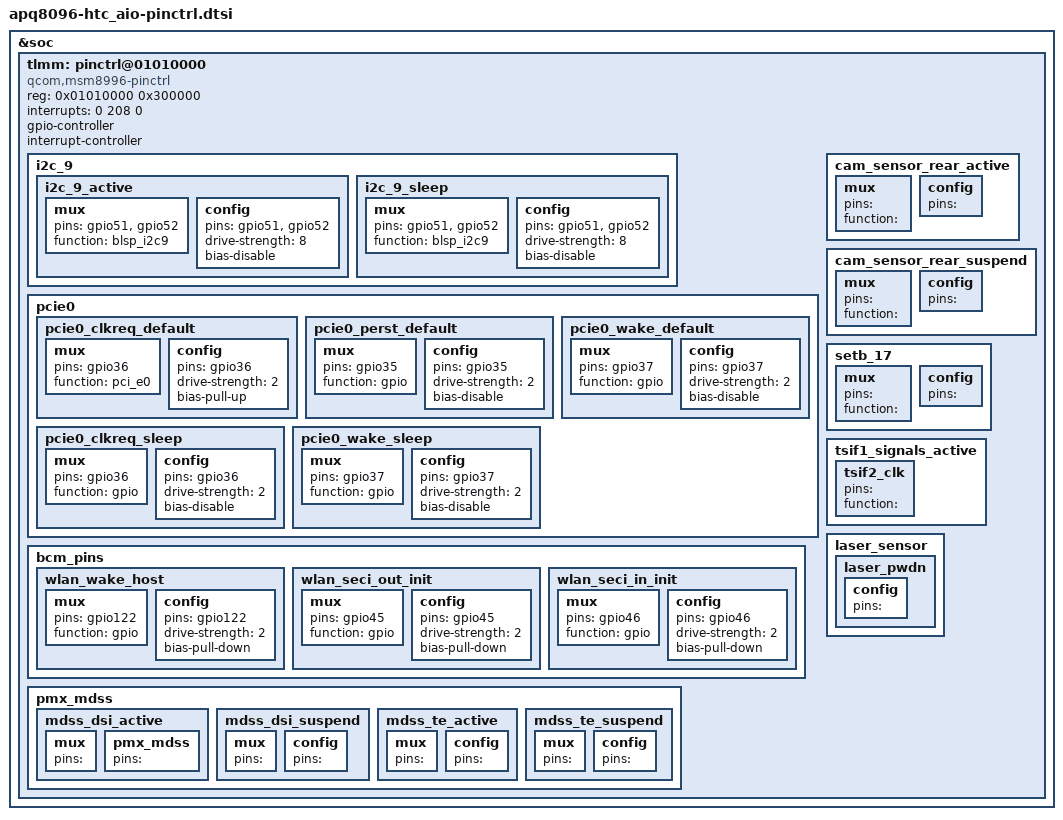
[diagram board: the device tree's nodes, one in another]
/* Copyright (c) 2016, The Linux Foundation. All rights reserved.
 *
 * This program is free software; you can redistribute it and/or modify
 * it under the terms of the GNU General Public License version 2 and
 * only version 2 as published by the Free Software Foundation.
 *
 * This program is distributed in the hope that it will be useful,
 * but WITHOUT ANY WARRANTY; without even the implied warranty of
 * MERCHANTABILITY or FITNESS FOR A PARTICULAR PURPOSE.  See the
 * GNU General Public License for more details.
 */

&soc {
	tlmm: pinctrl@01010000 {
		compatible = "qcom,msm8996-pinctrl";
		reg = <0x01010000 0x300000>;
		interrupts = <0 208 0>;
		gpio-controller;
		#gpio-cells = <2>;
		interrupt-controller;
		#interrupt-cells = <2>;

		i2c_9 {
			i2c_9_active: i2c_9_active {
				mux {
					pins = "gpio51", "gpio52";
					function = "blsp_i2c9";
				};

				config {
					pins = "gpio51", "gpio52";
					drive-strength = <8>;
					bias-disable;
				};
			};

			i2c_9_sleep: i2c_9_sleep {
				mux {
					pins = "gpio51", "gpio52";
					function = "blsp_i2c9";
				};

				config {
					pins = "gpio51", "gpio52";
					drive-strength = <8>;
					bias-disable;
				};
			};
		};

		pcie0 {
			pcie0_clkreq_default: pcie0_clkreq_default {
				mux {
					pins = "gpio36";
					function = "pci_e0";
				};

				config {
					pins = "gpio36";
					drive-strength = <2>;
					bias-pull-up;
				};
			};

			pcie0_perst_default: pcie0_perst_default {
				mux {
					pins = "gpio35";
					function = "gpio";
				};

				config {
					pins = "gpio35";
					drive-strength = <2>;
					/* HTC_WIFI_START */
					// ** remove orignal code
					//bias-pull-down;
					// ** add new code
					bias-disable;
					/* HTC_WIFI_END */
				};
			};
			pcie0_wake_default: pcie0_wake_default {
				mux {
					pins = "gpio37";
					function = "gpio";
				};

				config {
					pins = "gpio37";
					drive-strength = <2>;
					/* HTC_WIFI_START */
					// ** remove original code
					//bias-pull-up;
					// ** add new code
					bias-disable;
					/* HTC_WIFI_END */
				};
			};

			pcie0_clkreq_sleep: pcie0_clkreq_sleep {
				mux {
					pins = "gpio36";
					function = "gpio";
				};

				config {
					pins = "gpio36";
					drive-strength = <2>;
					bias-disable;
				};
			};

			pcie0_wake_sleep: pcie0_wake_sleep {
				mux {
					pins = "gpio37";
					function = "gpio";
				};

				config {
					pins = "gpio37";
					drive-strength = <2>;
					bias-disable;
				};
			};
		};

		/* HTC_WIFI_START */
		bcm_pins {
			wlan_wake_host: wlan_wake_host {
				mux {
					pins = "gpio122";
					function = "gpio";
				};

				config {
					pins = "gpio122";
					drive-strength = <2>;   /* 2 mA */
					bias-pull-down;         /* PULL DOWN */
				};
			};
			wlan_seci_out_init: wlan_seci_out_init {
				mux {
					pins = "gpio45";
					function = "gpio";
				};

				config {
					pins = "gpio45";
					drive-strength = <2>;   /* 2 mA */
					bias-pull-down;         /* PULL DOWN */
				};
			};
			wlan_seci_in_init: wlan_seci_in_init {
				mux {
					pins = "gpio46";
					function = "gpio";
				};

				config {
					pins = "gpio46";
					drive-strength = <2>;   /* 2 mA */
					bias-pull-down;         /* PULL DOWN */
				};
			};
		};
		/* HTC_WIFI_END */
		/* HTC_DISP_STASRT */
		/* Remove GPIO 93 & 94 */
		cam_sensor_rear_active {
			mux {
				pins = "";
				function = "";
			};

			config {
				pins = "";
			};
		};
		cam_sensor_rear_suspend {
			mux {
				pins = "";
				function = "";
			};
			config {
				pins = "";
			};
		};
		setb_17 {
			mux {
				pins = "";
				function = "";
			};
			config {
				pins = "";
			};
		};
		tsif1_signals_active {
			tsif2_clk {
				pins = "";
				function = "";
			};
		};
		laser_sensor {
			laser_pwdn:laser_pwdn {
				config {
					pins = "";
				};
			};
		};
		/* Remove GPIO 8 & 10 */
		pmx_mdss {
			mdss_dsi_active {
				mux {
					pins = "";
				};

				pmx_mdss {
					pins = "";
				};
			};
			mdss_dsi_suspend {
				mux {
					pins = "";
				};

				config {
					pins = "";
				};
			};
			mdss_te_active {
				mux {
					pins = "";
				};
				config {
					pins = "";
				};
			};
			mdss_te_suspend {
				mux {
					pins = "";
				};
				config {
					pins = "";
				};
			};
		};
		/* HTC_DISP_END */
	};
};
